# STM32WBA65 register map
File version: 1.0
CPU: CM33 r0p1, little endian, MPU, FPU, 4 interrupt priority bits
Registers are 32-bit, read-write, reset 0x0 unless marked. A register's access mark holds for its fields unless they carry their own. Offsets are from the block's base; [hi:lo] are bit positions; {n}, {i} and the like mark numbered series; 'fields as' and 'values as' point back to an identical list.

## HSEM — HSEM address block description
Base 0x420C1C00
Same registers: SEC_HSEM 0x520C1C00
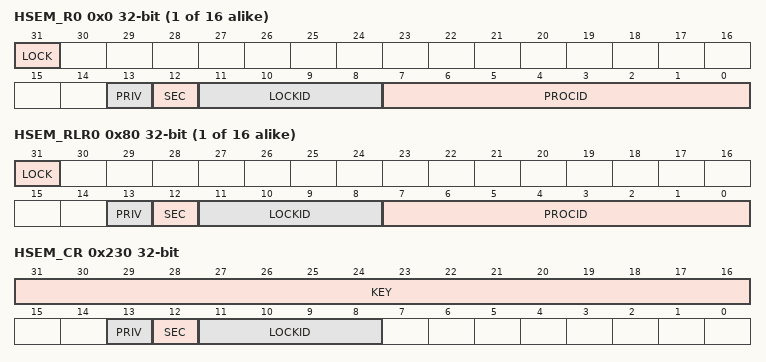
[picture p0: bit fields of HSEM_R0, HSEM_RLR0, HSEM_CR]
{0x0+4i} HSEM_R{i} (i=0..15) — HSEM register semaphore {i}
  [31] LOCK — Lock indication
    0=On write free semaphore (only when LOCKID and PROCID match), on read semaphore is free; 1=On write try to lock semaphore, on read semaphore is locked
  [13] PRIV — Semaphore privilege
    0=Semaphore free or locked by unprivileged compartment; 1=Semaphore locked by privilege compartment
  [12] SEC — Semaphore secure
    0=Semaphore free or locked by non-secure compartment; 1=Semaphore locked by secure compartment
  [11:8] LOCKID — Semaphore LOCKID
  [7:0] PROCID — Semaphore PROCID
{0x80+4i} HSEM_RLR{i} ro (i=0..15) — HSEM read lock register semaphore {i}
  [31] LOCK — Lock indication
  [13] PRIV — Semaphore privilege
    0=Semaphore free or locked by unprivileged compartment; 1=Semaphore locked by privileged compartment
  [12] SEC — Semaphore secure.
    values as HSEM_R0.SEC
  [11:8] LOCKID — Semaphore LOCKID
  [7:0] PROCID — Semaphore processor ID
0x100 HSEM_IER — HSEM non-secure interrupt enable register
  [15:0] ISE — Non-secure Interrupt semaphore x enable bit
    0=Non-secure Interrupt generation for semaphore x disabled (masked); 1=Non-secure Interrupt generation for semaphore x enabled (not masked)
0x104 HSEM_ICR — HSEM non-secure interrupt clear register
  [15:0] ISC — Non-secure Interrupt semaphore x clear bit
    0=non-secure Interrupt semaphore x status ISFx and masked status MISFx not affected; 1=non-secure Interrupt semaphore x status ISFx and masked status MISFx cleared
0x108 HSEM_ISR ro — HSEM non-secure interrupt status register
  [15:0] ISF — Interrupt semaphore x status bit before enable (mask)
    0=Interrupt semaphore x status, no interrupt pending; 1=Interrupt semaphore x status, interrupt pending
0x10C HSEM_MISR ro — HSEM non-secure interrupt status register
  [15:0] MISF — Masked non-secure interrupt semaphore x status bit after enable (mask)
    0=non-secure interrupt semaphore x status after masking not pending; 1=non-secure interrupt semaphore x status after masking pending
0x180 HSEM_SIER — HSEM secure interrupt enable register
  [15:0] SISE — Secure interrupt semaphore x enable bit
    0=Secure interrupt generation for semaphore x is disabled (masked); 1=Secure interrupt generation for semaphore x is enabled (not masked)
0x184 HSEM_SICR — HSEM secure interrupt clear register
  [15:0] SISC — Secure interrupt semaphore x clear bit
    0=Secure interrupt semaphore x status ISFx and masked status MISFx not affected; 1=Secure interrupt semaphore x status ISFx and masked status MISFx cleared
0x188 HSEM_SISR ro — HSEM secure interrupt status register
  [15:0] SISF — Secure interrupt semaphore x status bit before enable (mask)
    0=Secure interrupt semaphore x status, no interrupt pending; 1=Secure interrupt semaphore x status, interrupt pending
0x18C HSEM_MSISR ro — HSEM secure masked interrupt status register
  [15:0] SMISF — Secure masked interrupt semaphore x status bit after enable (mask)
    0=Secure interrupt semaphore x status after masking not pending; 1=Secure interrupt semaphore x status after masking pending
0x200 HSEM_SECCFGR — HSEM security configuration register
  [15:0] SEC — Semaphore x security attribute
    0=Semaphore x non-security, can be accessed by both secure and non-secure processors; 1=Semaphore x security, can be accessed only by secure processors
0x210 HSEM_PRIVCFGR — HSEM privilege configuration register
  [15:0] PRIV — Semaphore x privilege attribute
    0=Semaphore x unprivileged, can be accessed by both privileged and unprivileged processors; 1=Semaphore x privileged, can be accessed only by privileged processors
0x230 HSEM_CR wo — HSEM clear register
  [31:16] KEY — Semaphore clear key
  [13] PRIV — PRIV value of semaphores to be cleared.
  [12] SEC — SEC value of semaphores to be cleared.
  [11:8] LOCKID — LOCKID of semaphores to be cleared
0x234 HSEM_KEYR — HSEM clear semaphore key register
  [31:16] KEY — Semaphore clear key
